# ESP32-S3 register map
Vendor: ESPRESSIF SYSTEMS (SHANGHAI) CO., LTD.; Series: ESP32 S-Series; File version: 22
CPU: Xtensa LX7 r0p0, little endian, no MPU, FPU, 0 interrupt priority bits
Address unit: 32 bits
Registers are 32-bit, read-write, reset 0x0 unless marked. A register's access mark holds for its fields unless they carry their own. Offsets are from the block's base; [hi:lo] are bit positions; {n}, {i} and the like mark numbered series.

## PERI_BACKUP — PERI_BACKUP Peripheral
Base 0x6002A000
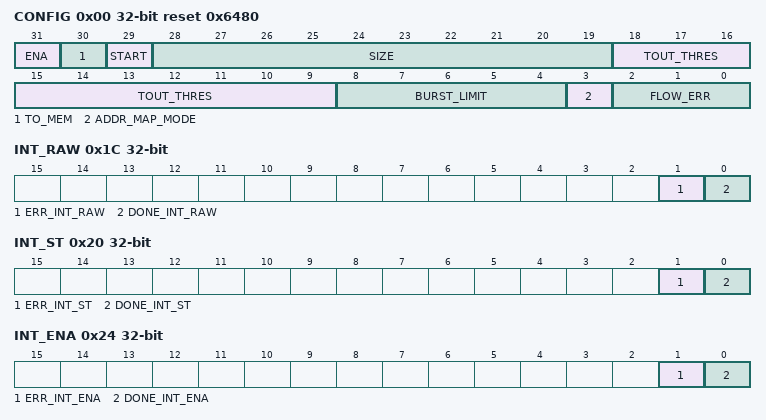
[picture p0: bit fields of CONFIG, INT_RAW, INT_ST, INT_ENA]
0x00 CONFIG access per field reset 0x6480 — x
  [31] ENA rw — x
  [30] TO_MEM rw — x
  [29] START wo — x
  [28:19] SIZE rw — x
  [18:9] TOUT_THRES rw — x
  [8:4] BURST_LIMIT rw — x
  [3] ADDR_MAP_MODE rw — x
  [2:0] FLOW_ERR ro — x
0x04 APB_ADDR — x
  [31:0] APB_START_ADDR
0x08 MEM_ADDR — x
  [31:0] MEM_START_ADDR
{0xC+4i} REG_MAP{i} (i=0..3) — x
0x1C INT_RAW ro — x
  [1] ERR_INT_RAW — x
  [0] DONE_INT_RAW — x
0x20 INT_ST ro — x
  [1] ERR_INT_ST — x
  [0] DONE_INT_ST — x
0x24 INT_ENA — x
  [1] ERR_INT_ENA — x
  [0] DONE_INT_ENA — x
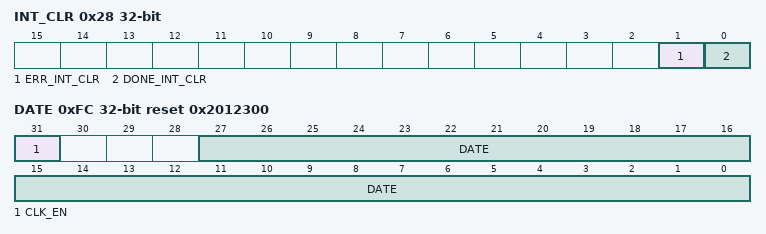
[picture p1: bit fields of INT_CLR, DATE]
0x28 INT_CLR wo — x
  [1] ERR_INT_CLR — x
  [0] DONE_INT_CLR — x
0xFC DATE reset 0x2012300 — x
  [31] CLK_EN — register file clk gating
  [27:0] DATE — x

## RNG — Hardware Random Number Generator
Base 0x60034F6C
0x110 DATA access not given — Random number data

## RSA — RSA (Rivest Shamir Adleman) Accelerator
Base 0x6003C000
{0x0+i} M_MEM[{i}] (i=0..511) 8-bit access not given — Memory M
{0x200+i} Z_MEM[{i}] (i=0..511) 8-bit access not given — Memory Z
{0x400+i} Y_MEM[{i}] (i=0..511) 8-bit access not given — Memory Y
{0x600+i} X_MEM[{i}] (i=0..511) 8-bit access not given — Memory X
0x800 M_PRIME — RSA M' register
  [31:0] M_PRIME — Stores M'
0x804 MODE — RSA length mode register
  [6:0] MODE — Stores the RSA length mode
0x808 CLEAN ro — RSA clean register
  [0] CLEAN — The content of this bit is 1 when memories complete initialization.
0x80C MODEXP_START wo — Modular exponentiation trigger register.
  [0] MODEXP_START — Set this bit to 1 to start the modular exponentiation.
0x810 MODMULT_START wo — Modular multiplication trigger register.
  [0] MODMULT_START — Set this bit to 1 to start the modular multiplication
0x814 MULT_START wo — Normal multiplication trigger register.
  [0] MULT_START — Set this bit to 1 to start the multiplicaiton.
0x818 IDLE ro — RSA idle register
  [0] IDLE — The content of this bit is 1 when the RSA accelerator is idle.
0x81C CLEAR_INTERRUPT wo — RSA interrupt clear register
  [0] CLEAR_INTERRUPT — set this bit to 1 to clear the RSA interrupt.
0x820 CONSTANT_TIME reset 0x1 — CONSTANT_TIME option control register
  [0] CONSTANT_TIME — Controls the CONSTANT_TIME option. 0: acceleration. 1: no acceleration(by default).
0x824 SEARCH_ENABLE — SEARCH option enable register
  [0] SEARCH_ENABLE — Controls the SEARCH option. 0: no acceleration(by default). 1: acceleration.
0x828 SEARCH_POS — RSA search position configure register
  [11:0] SEARCH_POS — This field is used to configure the starting search position when the acceleration option of SEARCH is used.
0x82C INTERRUPT_ENA — RSA interrupt enable register
  [0] INTERRUPT_ENA — Set this bit to 1 to enable the RSA interrupt. This option is enabled by default.
0x830 DATE reset 0x20191231 — RSA version control register
  [29:0] DATE — rsa version information

## SHA — SHA (Secure Hash Algorithm) Accelerator
Base 0x6003B000
0x00 MODE — Initial configuration register.
  [2:0] MODE — sha mode
0x04 T_STRING — SHA 512/t configuration register 0.
  [31:0] T_STRING — sha t_string(used if and only if mode == sha_256/t)
0x08 T_LENGTH — SHA 512/t configuration register 1.
  [5:0] T_LENGTH — sha t_length(used if and only if mode == sha_256/t)
0x0C DMA_BLOCK_NUM — DMA configuration register 0.
  [5:0] DMA_BLOCK_NUM — dma-sha block number
0x10 START ro — Typical SHA configuration register 0.
  [31:1] START — reserved.
0x14 CONTINUE ro — Typical SHA configuration register 1.
  [31:1] CONTINUE — reserved.
0x18 BUSY ro
  [0] STATE — sha busy state. 1'b0: idle 1'b1: busy
0x1C DMA_START wo — DMA configuration register 1.
  [0] DMA_START — start dma-sha
0x20 DMA_CONTINUE wo — DMA configuration register 2.
  [0] DMA_CONTINUE — continue dma-sha
0x24 CLEAR_IRQ wo — Interrupt clear register.
  [0] CLEAR_INTERRUPT — clear sha interrupt
0x28 IRQ_ENA — Interrupt enable register.
  [0] INTERRUPT_ENA — sha interrupt enable register. 1'b0: disable(default) 1'b1: enable
0x2C DATE reset 0x20190402
  [29:0] DATE — sha date information/ sha version information
{0x40+i} H_MEM[{i}] (i=0..63) 8-bit access not given — Sha H memory which contains intermediate hash or finial hash.
{0x80+i} M_MEM[{i}] (i=0..63) 8-bit access not given — Sha M memory which contains message.
